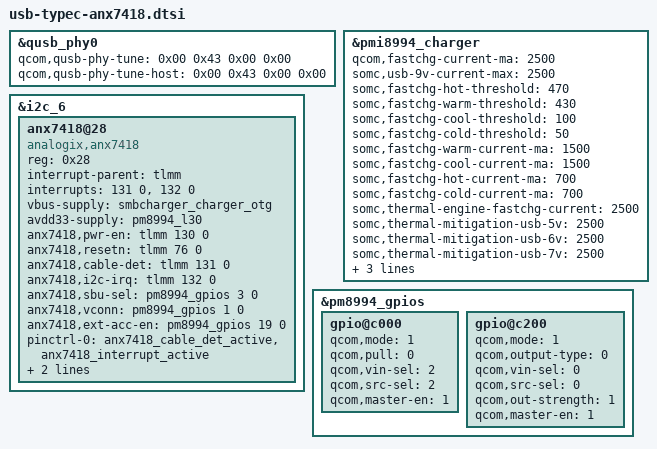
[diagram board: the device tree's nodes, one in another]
/* Copyright (c) 2015, The Linux Foundation. All rights reserved.
 *
 * This program is free software; you can redistribute it and/or modify
 * it under the terms of the GNU General Public License version 2 and
 * only version 2 as published by the Free Software Foundation.
 *
 * This program is distributed in the hope that it will be useful,
 * but WITHOUT ANY WARRANTY; without even the implied warranty of
 * MERCHANTABILITY or FITNESS FOR A PARTICULAR PURPOSE.  See the
 * GNU General Public License for more details.
 */

/* From usb dtsi - same tuning */
&qusb_phy0 {
	qcom,qusb-phy-tune = <0x00 0x43 0x00 0x00>;
	qcom,qusb-phy-tune-host = <0x00 0x43 0x00 0x00>;
};

/* 
 * Battery temp readings aren't functioning as expected, and as such, 
 * the temp mitigations are temporarily 'disabled' below until we
 * manage to fix it. Thankfully the G5 doesn't heat up much while 
 * charging at those rates anyway.
 */
&pmi8994_charger {
	qcom,fastchg-current-ma = <2500>;
	somc,usb-9v-current-max = <2500>;
	somc,fastchg-hot-threshold = <470>;
	somc,fastchg-warm-threshold = <430>;
	somc,fastchg-cool-threshold = <100>;
	somc,fastchg-cold-threshold = <50>;
	somc,fastchg-warm-current-ma = <1500>;
	somc,fastchg-cool-current-ma = <1500>;
	somc,fastchg-hot-current-ma  = <700>;
	somc,fastchg-cold-current-ma = <700>;
	somc,thermal-engine-fastchg-current = <2500>;
	somc,thermal-mitigation-usb-5v = <2500>;
	somc,thermal-mitigation-usb-6v = <2500>;
	somc,thermal-mitigation-usb-7v = <2500>;
	somc,thermal-mitigation-usb-8v = <2500>;
	somc,thermal-mitigation-usb-9v = <2500>;
	somc,typec-current-max = <2500>;
};

&i2c_6 {
	anx7418@28 {
		compatible = "analogix,anx7418";
		reg = <0x28>;

		interrupt-parent = <&tlmm>;
		interrupts = <131 0>, <132 0>;

		vbus-supply = <&smbcharger_charger_otg>;
		avdd33-supply = <&pm8994_l30>;

		anx7418,pwr-en = <&tlmm 130 0>;
		anx7418,resetn = <&tlmm 76 0>;
		anx7418,cable-det = <&tlmm 131 0>;
		anx7418,i2c-irq = <&tlmm 132 0>;
		anx7418,sbu-sel = <&pm8994_gpios 3 0>;
		anx7418,vconn = <&pm8994_gpios 1 0>;
		anx7418,ext-acc-en = <&pm8994_gpios 19 0>;

		status = "ok";

		pinctrl-names = "default", "sleep";
		pinctrl-0	= <&anx7418_cable_det_active &anx7418_interrupt_active>;
		pinctrl-1	= <&anx7418_cable_det_sleep &anx7418_interrupt_sleep>;
	};
};

&pm8994_gpios {
	gpio@c000 {	/* GPIO 1 VCONN */
		qcom,mode = <1>;		/* Digital output */
		qcom,pull = <0>;
		qcom,vin-sel = <2>;		/* VIN2 */
		qcom,src-sel = <2>;		/* GPIO */
		qcom,master-en = <1>;		/* Enable GPIO */
		status = "okay";
	};

	gpio@c200 {	/* GPIO 3 SBU_SEL */
		qcom,mode = <1>;		/* Digital output */
		qcom,output-type = <0>;		/* MOS logic */
		qcom,vin-sel = <0>;		/* VPH_PWR */
		qcom,src-sel = <0>;		/* Constant */
		qcom,out-strength = <1>;	/* High drive strength */
		qcom,master-en = <1>;		/* Enable GPIO */
		status = "okay";
	};
};
